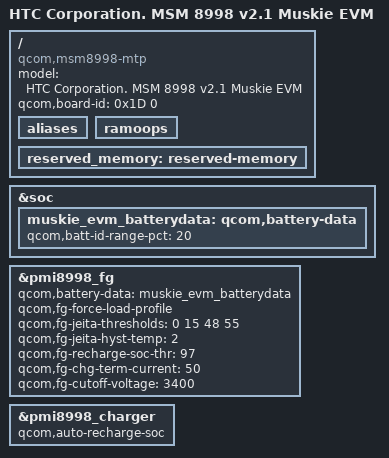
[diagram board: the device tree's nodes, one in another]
/* Copyright (c) 2016, The Linux Foundation. All rights reserved.
 *
 * This program is free software; you can redistribute it and/or modify
 * it under the terms of the GNU General Public License version 2 and
 * only version 2 as published by the Free Software Foundation.
 *
 * This program is distributed in the hope that it will be useful,
 * but WITHOUT ANY WARRANTY; without even the implied warranty of
 * MERCHANTABILITY or FITNESS FOR A PARTICULAR PURPOSE.  See the
 * GNU General Public License for more details.
 */


/dts-v1/;

/* WIP: Device tree overlay: SoC dtbo */
#include "../qcom/msm8998-v2.1.dtsi"

/ {
	aliases: aliases {};
	ramoops: ramoops {};
	reserved_memory: reserved-memory {};
};

/*
 * TODO: Device tree overlay:
 * below part is to be removed and the information will be
 * provided through DTB/DTBO partition dt_table_entry.
 */

/ {
	model = "HTC Corporation. MSM 8998 v2.1 Muskie EVM";
	compatible = "qcom,msm8998-mtp", "qcom,msm8998", "qcom,mtp";
	qcom,board-id = <0x1D 0>;
};

/* WIP: Device tree overlay: overlay dtbo */
#include "msm8998-htc_muskie-evm.dtsi"
&soc {
	muskie_evm_batterydata: qcom,battery-data {
		qcom,batt-id-range-pct = <20>;
		#include "batterydata-evm-xa.dtsi"
	};
};

&pmi8998_fg {
	qcom,battery-data = <&muskie_evm_batterydata>;
	qcom,fg-force-load-profile;
	qcom,fg-jeita-thresholds = <0 15 48 55>;
	qcom,fg-jeita-hyst-temp = <2>;
	qcom,fg-recharge-soc-thr = <97>;
	qcom,fg-chg-term-current = <50>;
	qcom,fg-cutoff-voltage = <3400>;
};

&pmi8998_charger {
	qcom,auto-recharge-soc;
};
